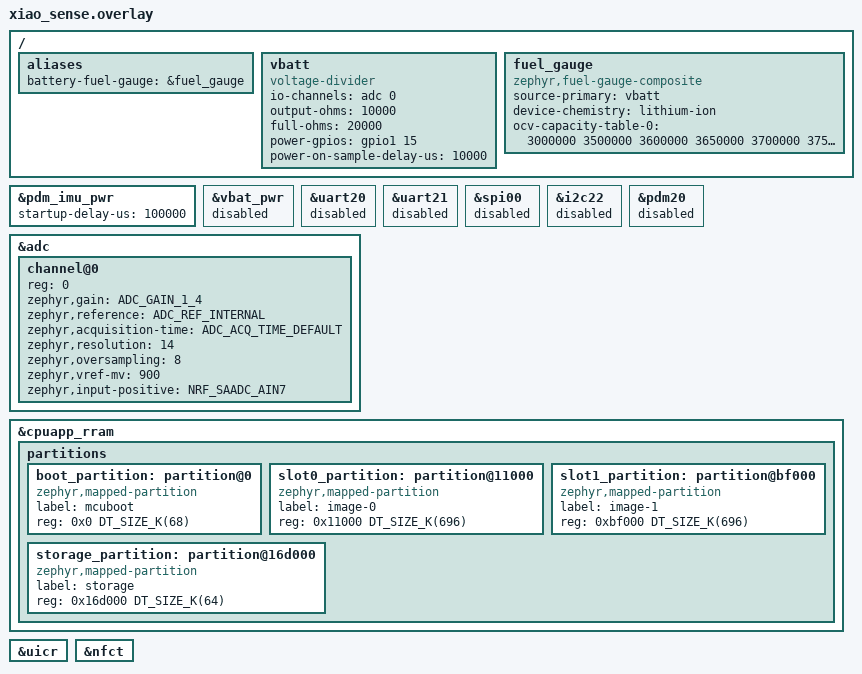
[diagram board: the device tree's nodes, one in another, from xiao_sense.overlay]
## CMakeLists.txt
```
# SPDX-License-Identifier: Apache-2.0

cmake_minimum_required(VERSION 3.20.0)

find_package(Zephyr REQUIRED HINTS $ENV{ZEPHYR_BASE})
project(putttrack_tag)

target_sources(app PRIVATE src/main.c src/pickup_shadow_v0.c)

target_sources_ifdef(CONFIG_PUTTTRACK_XIAO_SENSE app PRIVATE src/xiao_sense.c)
target_sources_ifdef(CONFIG_PUTTTRACK_NFC_READ_LED app PRIVATE src/nfc_read_led.c)
```

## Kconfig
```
# SPDX-License-Identifier: Apache-2.0

source "Kconfig.zephyr"

menu "PuttTrack Tag options"

config PUTTTRACK_XIAO_SENSE
 bool "Use the XIAO nRF54L15 Sense single-IMU backend"
 default n

config PUTTTRACK_FIRMWARE_VERSION
 string "Application version reported over BLE"
 default "0.1.21"


config PUTTTRACK_NFC_SERVICE
	bool "Enable the experimental NFC service record"
	default n
	help
	  Build the Type 4 Tag NDEF service record and one-shot bounded
	  fast-BLE discovery window used by the PCA20072 NFC feasibility experiment.
	  This option does not make NFC an authenticated transport and does not
	  replace encrypted BLE SMP or signed OTA.

config PUTTTRACK_NFC_SYSTEM_OFF_TEST
	bool "Enable explicit NFC System OFF wake experiment"
	depends on PUTTTRACK_NFC_SERVICE
	default n
	help
	  Add an encrypted BLE SMP command that enters System OFF after a short
	  delay. NFC field sensing remains armed as a wake source. This is an
	  explicit laboratory operation only; normal power policies never enter
	  System OFF automatically.

config PUTTTRACK_NFC_READ_LED
	bool "Flash board user LED on a complete NDEF read event"
	depends on PUTTTRACK_NFC_SERVICE && GPIO
	default n
	help
	  Temporary bench feedback: 150 ms pulse, at most once per second.
	  Indicates a tag-side read event, not reader CRC success or BLE identity.

endmenu
```

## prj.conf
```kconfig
# Repository-owned PuttTrack Tag firmware: BLE identity/health, raw motion and OTA.

CONFIG_BOOTLOADER_MCUBOOT=y
CONFIG_MCUBOOT_IMGTOOL_SIGN_VERSION="0.1.21+0"

# MCUboot image management over encrypted BLE SMP.
CONFIG_NET_BUF=y
CONFIG_ZCBOR=y
CONFIG_CRC=y
CONFIG_FLASH=y
CONFIG_FLASH_MAP=y
CONFIG_STREAM_FLASH=y
CONFIG_IMG_MANAGER=y
CONFIG_MCUMGR=y
CONFIG_MCUMGR_GRP_IMG=y
CONFIG_MCUMGR_GRP_OS=y
CONFIG_MCUMGR_TRANSPORT_BT=y
CONFIG_MCUMGR_TRANSPORT_BT_REASSEMBLY=y
CONFIG_MCUMGR_TRANSPORT_BT_CONN_PARAM_CONTROL=y
CONFIG_MCUMGR_TRANSPORT_BT_PERM_RW_ENCRYPT=y
CONFIG_MCUMGR_TRANSPORT_NETBUF_SIZE=8192
CONFIG_MCUMGR_TRANSPORT_WORKQUEUE_STACK_SIZE=4608

# BLE peripheral and secure connections. The lab build uses encrypted Just Works
# pairing; authenticated/MITM access needs a future physical or OOB workflow.
CONFIG_BT=y
CONFIG_BT_PERIPHERAL=y
CONFIG_BT_SMP=y
CONFIG_BT_DEVICE_NAME="PuttTrack-Tag-v0.1"
CONFIG_BT_MAX_CONN=1
CONFIG_BT_L2CAP_TX_MTU=498
CONFIG_BT_BUF_ACL_RX_SIZE=502
CONFIG_BT_BUF_ACL_TX_SIZE=502
CONFIG_BT_CTLR_DATA_LENGTH_MAX=251

# Tag sensors enabled by the upstream nrf54l15tag board definition.
CONFIG_SENSOR=y
CONFIG_I2C=y
CONFIG_SPI=y
CONFIG_ADXL367=y
CONFIG_ADXL367_TRIGGER_GLOBAL_THREAD=y
CONFIG_ADXL367_ACTIVITY_THRESHOLD=200
CONFIG_ADXL367_ACTIVITY_TIME=2
CONFIG_ADXL367_INACTIVITY_DETECTION_MODE=n
CONFIG_BMI270=y
CONFIG_BMI270_TRIGGER_NONE=y

# Allow the application to suspend the unused BMI270 SPI controller and apply
# its low-power pinctrl state while the Tag is idle.
CONFIG_PM_DEVICE=y

# The official nRF54L15 Tag fuel-gauge setup samples VDD with SAADC and maps
# the CR2032 open-circuit voltage to an explicitly approximate percentage.
CONFIG_ADC=y
CONFIG_FUEL_GAUGE=y
CONFIG_FUEL_GAUGE_COMPOSITE=y

# Stable hardware identity, boot identity and reset diagnostics.
CONFIG_HWINFO=y
CONFIG_ENTROPY_GENERATOR=y
CONFIG_REBOOT=y

# The Tag has no selected debug UART. Runtime diagnostics are part of the BLE
# status record rather than an inaccessible console.
CONFIG_CONSOLE=n
CONFIG_UART_CONSOLE=n
CONFIG_SERIAL=n
CONFIG_UART_MCUMGR=n
CONFIG_MCUMGR_TRANSPORT_UART=n
CONFIG_SHELL=n
CONFIG_LOG=n

CONFIG_MAIN_STACK_SIZE=4096
CONFIG_SYSTEM_WORKQUEUE_STACK_SIZE=4096

# Keep the commissioned BLE identity and bonds across System OFF and reset.
CONFIG_SETTINGS=y
CONFIG_BT_SETTINGS=y
CONFIG_NVS=y
CONFIG_SETTINGS_NVS=y
CONFIG_BT_DEVICE_NAME_DYNAMIC=y
```

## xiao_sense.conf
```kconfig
# Repository-owned PuttTrack Tag firmware: BLE identity/health, raw motion and OTA.

CONFIG_BOOTLOADER_MCUBOOT=y
CONFIG_MCUBOOT_IMGTOOL_SIGN_VERSION="0.2.7+0"

# MCUboot image management over encrypted BLE SMP.
CONFIG_NET_BUF=y
CONFIG_ZCBOR=y
CONFIG_CRC=y
CONFIG_FLASH=y
CONFIG_FLASH_MAP=y
CONFIG_STREAM_FLASH=y
CONFIG_IMG_MANAGER=y
CONFIG_MCUMGR=y
CONFIG_MCUMGR_GRP_IMG=y
CONFIG_MCUMGR_GRP_OS=y
CONFIG_MCUMGR_TRANSPORT_BT=y
CONFIG_MCUMGR_TRANSPORT_BT_REASSEMBLY=y
CONFIG_MCUMGR_TRANSPORT_BT_CONN_PARAM_CONTROL=y
CONFIG_MCUMGR_TRANSPORT_BT_PERM_RW_ENCRYPT=y
CONFIG_MCUMGR_TRANSPORT_NETBUF_SIZE=8192
CONFIG_MCUMGR_TRANSPORT_WORKQUEUE_STACK_SIZE=4608

# BLE peripheral and secure connections. The lab build uses encrypted Just Works
# pairing; authenticated/MITM access needs a future physical or OOB workflow.
CONFIG_BT=y
CONFIG_BT_PERIPHERAL=y
CONFIG_BT_SMP=y
CONFIG_BT_MAX_PAIRED=2
CONFIG_BT_DEVICE_NAME="PuttTrack-Tag-v0.1"
CONFIG_BT_MAX_CONN=1
CONFIG_BT_L2CAP_TX_MTU=498
CONFIG_BT_BUF_ACL_RX_SIZE=502
CONFIG_BT_BUF_ACL_TX_SIZE=502
CONFIG_BT_CTLR_DATA_LENGTH_MAX=251

# XIAO owns one LSM6DS3TR-C via the serialized register backend.
CONFIG_PUTTTRACK_XIAO_SENSE=y
CONFIG_PUTTTRACK_FIRMWARE_VERSION="0.2.7"
CONFIG_SENSOR=y
CONFIG_I2C=y
CONFIG_GPIO=y
CONFIG_REGULATOR=y
CONFIG_REGULATOR_FIXED=y
CONFIG_LSM6DSL=n
CONFIG_PM_DEVICE=y
CONFIG_ADC=y
CONFIG_FUEL_GAUGE=y
CONFIG_FUEL_GAUGE_COMPOSITE=y

# Stable hardware identity, boot identity and reset diagnostics.
CONFIG_HWINFO=y
CONFIG_ENTROPY_GENERATOR=y
CONFIG_REBOOT=y

# The Tag has no selected debug UART. Runtime diagnostics are part of the BLE
# status record rather than an inaccessible console.
CONFIG_CONSOLE=n
CONFIG_UART_CONSOLE=n
CONFIG_SERIAL=n
CONFIG_UART_MCUMGR=n
CONFIG_MCUMGR_TRANSPORT_UART=n
CONFIG_SHELL=n
CONFIG_LOG=n

CONFIG_MAIN_STACK_SIZE=4096
CONFIG_SYSTEM_WORKQUEUE_STACK_SIZE=4096

# NFC Type 4 read/write service and an explicit, recoverable System OFF experiment.
CONFIG_PUTTTRACK_NFC_SERVICE=y
CONFIG_NFC_T4T_NRFXLIB=y
CONFIG_NFC_NDEF=y
CONFIG_NFC_NDEF_MSG=y
CONFIG_NFC_NDEF_RECORD=y
CONFIG_NFC_NDEF_URI_REC=y
CONFIG_NFC_NDEF_URI_MSG=y
CONFIG_PUTTTRACK_NFC_SYSTEM_OFF_TEST=y
CONFIG_POWEROFF=y

# Preserve BLE identity and pairing keys across MCUboot trial/rollback/reset.
CONFIG_SETTINGS=y
CONFIG_BT_SETTINGS=y
CONFIG_NVS=y
CONFIG_SETTINGS_NVS=y

CONFIG_BT_DEVICE_NAME_DYNAMIC=y
CONFIG_PUTTTRACK_NFC_READ_LED=y
```

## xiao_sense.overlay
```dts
/* Seeed XIAO Sense: own the IMU supply sequencing; keep OTA slot layout. */
/delete-node/ &imu_power_default_on;
&pdm_imu_pwr {
 /delete-property/ regulator-boot-on;
 startup-delay-us = <100000>;
};
/* The divider driver owns VBAT_EN and only powers it during measurement. */
&vbat_pwr { status = "disabled"; };
&uart20 { status = "disabled"; };
&uart21 { status = "disabled"; };
&spi00 { status = "disabled"; };
&i2c22 { status = "disabled"; };
&pdm20 { status = "disabled"; };
/ {
 aliases { battery-fuel-gauge = &fuel_gauge; };
 vbatt: vbatt {
  compatible = "voltage-divider";
  io-channels = <&adc 0>;
  output-ohms = <10000>;
  full-ohms = <20000>;
  power-gpios = <&gpio1 15 GPIO_ACTIVE_HIGH>;
  power-on-sample-delay-us = <10000>;
 };
 fuel_gauge: fuel_gauge {
  compatible = "zephyr,fuel-gauge-composite";
  source-primary = <&vbatt>;
  device-chemistry = "lithium-ion";
  /* Generic Li-ion OCV estimate, NOT a calibrated battery or presence detector. */
  ocv-capacity-table-0 = <3000000 3500000 3600000 3650000 3700000
                        3750000 3800000 3900000 4000000 4100000 4200000>;

 };
};
&adc {
 #address-cells = <1>;
 #size-cells = <0>;
 channel@0 {
  reg = <0>;
  zephyr,gain = "ADC_GAIN_1_4";
  zephyr,reference = "ADC_REF_INTERNAL";
  zephyr,acquisition-time = <ADC_ACQ_TIME_DEFAULT>;
  zephyr,resolution = <14>;
  zephyr,oversampling = <8>;
  zephyr,vref-mv = <900>;
  zephyr,input-positive = <NRF_SAADC_AIN7>;
 };
};
/delete-node/ &boot_partition;
/delete-node/ &slot0_partition;
/delete-node/ &slot1_partition;
/delete-node/ &storage_partition;

&cpuapp_rram {
	partitions {
		boot_partition: partition@0 {
			compatible = "zephyr,mapped-partition";
			label = "mcuboot";
			reg = <0x0 DT_SIZE_K(68)>;
		};

		slot0_partition: partition@11000 {
			compatible = "zephyr,mapped-partition";
			label = "image-0";
			reg = <0x11000 DT_SIZE_K(696)>;
		};

		slot1_partition: partition@bf000 {
			compatible = "zephyr,mapped-partition";
			label = "image-1";
			reg = <0xbf000 DT_SIZE_K(696)>;
		};

		storage_partition: partition@16d000 {
			compatible = "zephyr,mapped-partition";
			label = "storage";
			reg = <0x16d000 DT_SIZE_K(64)>;
		};
	};
};

&uicr { /delete-property/ nfct-pins-as-gpios; };
&nfct { status = "okay"; };
```

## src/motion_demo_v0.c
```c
#include "motion_demo_v0.h"

#include <string.h>

#define MICRO_F 1000000.0f
#define BASELINE_WINDOW_US 1000000ULL
#define IMPULSE_WINDOW_BEFORE_US 100000ULL
#define IMPULSE_WINDOW_AFTER_US 500000ULL
#define GYRO_WINDOW_US 1000000ULL
#define TRACKING_WINDOW_US 500000ULL
#define MIN_BASELINE_DURATION_US 900000ULL
#define MIN_TRACKING_SAMPLES 20U

_Static_assert(sizeof(struct motion_demo_v0) <=
                   MOTION_DEMO_V0_CONTEXT_RAM_BUDGET_BYTES,
               "motion demo context exceeds the research RAM budget");

struct motion_demo_window_stats {
    uint16_t count;
    uint64_t first_us;
    uint64_t last_us;
    float accel_norm_mean;
    float accel_norm_m2;
    float gyro_norm_sum;
    float gyro_norm_sq_sum;
    float gyro_vector_sum[3];
    bool invalid;
    bool gyro_clipped;
};

static float demo_absf(float value)
{
    return value < 0.0f ? -value : value;
}

static float demo_sqrtf(float value)
{
    if (value <= 0.0f) {
        return 0.0f;
    }
    float estimate = value > 1.0f ? value : 1.0f;
    for (size_t iteration = 0; iteration < 16U; iteration++) {
        estimate = 0.5f * (estimate + value / estimate);
    }
    return estimate;
}

static float vector_norm_micro(const int32_t vector[3])
{
    float squared = 0.0f;
    for (size_t axis = 0; axis < 3U; axis++) {
        float value = (float)vector[axis] / MICRO_F;
        squared += value * value;
    }
    return demo_sqrtf(squared);
}

static bool sample_is_valid(const struct motion_demo_v0_sample *sample)
{
    return sample->bmi270_valid && sample->sensor_error_bits == 0U;
}

static bool sample_gyro_clipped(const struct motion_demo_v0_sample *sample)
{
    for (size_t axis = 0; axis < 3U; axis++) {
        int64_t value = sample->gyro_micro_rads[axis];
        if (value < 0) {
            value = -value;
        }
        if (value >= MOTION_DEMO_V0_GYRO_CLIP_MICRO_RADS) {
            return true;
        }
    }
    return false;
}

static bool sample_is_active(const struct motion_demo_v0_sample *sample)
{
    float accel_norm = vector_norm_micro(sample->accel_micro_ms2);
    float gyro_norm = vector_norm_micro(sample->gyro_micro_rads);
    return demo_absf(accel_norm - MOTION_DEMO_V0_GRAVITY_MPS2) >=
               MOTION_DEMO_V0_ONSET_ACCEL_DEVIATION_MPS2 ||
           gyro_norm >= MOTION_DEMO_V0_ONSET_GYRO_RADS;
}

static uint16_t oldest_index(const struct motion_demo_v0 *context)
{
    return (uint16_t)((context->write_index + MOTION_DEMO_V0_BUFFER_SAMPLES -
                       context->count) %
                      MOTION_DEMO_V0_BUFFER_SAMPLES);
}

static const struct motion_demo_v0_sample *sample_at(
    const struct motion_demo_v0 *context, uint16_t logical_index)
{
    uint16_t index = (uint16_t)((oldest_index(context) + logical_index) %
                                MOTION_DEMO_V0_BUFFER_SAMPLES);
    return &context->samples[index];
}

static void store_sample(struct motion_demo_v0 *context,
                         const struct motion_demo_v0_sample *sample)
{
    context->samples[context->write_index] = *sample;
    context->write_index = (uint16_t)((context->write_index + 1U) %
                                      MOTION_DEMO_V0_BUFFER_SAMPLES);
    if (context->count < MOTION_DEMO_V0_BUFFER_SAMPLES) {
        context->count++;
    }
}

static bool set_state(struct motion_demo_v0 *context,
                      enum motion_demo_v0_state state,
                      uint64_t transition_us)
{
    if (context->state == state) {
        return false;
    }
    context->state = state;
    context->last_transition_us = transition_us;
    context->state_transition_count++;
    return true;
}

static void reset_candidate_features(struct motion_demo_v0 *context)
{
    context->baseline_stationary = false;
    context->pickup_rule_passed = false;
    context->rolling_rule_passed = false;
    context->vertical_impulse_milli_mps = 0;
    context->gyro_mean_milli_rads = 0;
    context->axis_consistency_milli = 0;
    context->onset_sequence = 0U;
    context->onset_us = 0U;
}

static void reset_history_after_fault(struct motion_demo_v0 *context)
{
    context->write_index = 0U;
    context->count = 0U;
    reset_candidate_features(context);
}

static void window_stats_add(struct motion_demo_window_stats *stats,
                             const struct motion_demo_v0_sample *sample)
{
    float accel_norm = vector_norm_micro(sample->accel_micro_ms2);
    float gyro_norm = vector_norm_micro(sample->gyro_micro_rads);
    stats->count++;
    if (stats->count == 1U) {
        stats->first_us = sample->source_monotonic_us;
        stats->accel_norm_mean = accel_norm;
    } else {
        float delta = accel_norm - stats->accel_norm_mean;
        stats->accel_norm_mean += delta / (float)stats->count;
        stats->accel_norm_m2 += delta *
                               (accel_norm - stats->accel_norm_mean);
    }
    stats->last_us = sample->source_monotonic_us;
    stats->gyro_norm_sum += gyro_norm;
    stats->gyro_norm_sq_sum += gyro_norm * gyro_norm;
    for (size_t axis = 0; axis < 3U; axis++) {
        stats->gyro_vector_sum[axis] +=
            (float)sample->gyro_micro_rads[axis] / MICRO_F;
    }
    stats->invalid |= !sample_is_valid(sample);
    stats->gyro_clipped |= sample_gyro_clipped(sample);
}

static struct motion_demo_window_stats window_stats(
    const struct motion_demo_v0 *context, uint64_t start_us, uint64_t end_us)
{
    struct motion_demo_window_stats stats = {0};
    for (uint16_t index = 0U; index < context->count; index++) {
        const struct motion_demo_v0_sample *sample = sample_at(context, index);
        if (sample->source_monotonic_us >= start_us &&
            sample->source_monotonic_us < end_us) {
            window_stats_add(&stats, sample);
        }
    }
    return stats;
}

static float window_accel_std(const struct motion_demo_window_stats *stats)
{
    if (stats->count < 2U) {
        return 0.0f;
    }
    return demo_sqrtf(stats->accel_norm_m2 / (float)stats->count);
}

static float window_gyro_rms(const struct motion_demo_window_stats *stats)
{
    if (stats->count == 0U) {
        return 0.0f;
    }
    return demo_sqrtf(stats->gyro_norm_sq_sum / (float)stats->count);
}

static float window_gyro_mean(const struct motion_demo_window_stats *stats)
{
    return stats->count == 0U ? 0.0f :
           stats->gyro_norm_sum / (float)stats->count;
}

static float window_axis_consistency(
    const struct motion_demo_window_stats *stats)
{
    float mean_norm = window_gyro_mean(stats);
    if (stats->count == 0U || mean_norm <= 0.000001f) {
        return 0.0f;
    }
    float squared = 0.0f;
    for (size_t axis = 0; axis < 3U; axis++) {
        float mean = stats->gyro_vector_sum[axis] / (float)stats->count;
        squared += mean * mean;
    }
    return demo_sqrtf(squared) / mean_norm;
}

static bool stationary_window(const struct motion_demo_v0 *context,
                              uint64_t end_us)
{
    uint64_t start_us = end_us > BASELINE_WINDOW_US ?
                        end_us - BASELINE_WINDOW_US : 0U;
    struct motion_demo_window_stats stats =
        window_stats(context, start_us, end_us + 1U);
    if (stats.count < MOTION_DEMO_V0_REQUIRED_BASELINE_SAMPLES ||
        stats.invalid || stats.last_us <= stats.first_us ||
        stats.last_us - stats.first_us < MIN_BASELINE_DURATION_US) {
        return false;
    }
    return window_accel_std(&stats) <=
               MOTION_DEMO_V0_STATIONARY_ACCEL_STD_MAX_MPS2 &&
           window_gyro_rms(&stats) <=
               MOTION_DEMO_V0_STATIONARY_GYRO_RMS_MAX_RADS;
}

static bool onset_block_ready(const struct motion_demo_v0 *context,
                              uint16_t *onset_logical_index)
{
    if (context->count < MOTION_DEMO_V0_ONSET_WINDOW_SAMPLES) {
        return false;
    }
    uint16_t start = (uint16_t)(context->count -
                                MOTION_DEMO_V0_ONSET_WINDOW_SAMPLES);
    uint16_t active = 0U;
    for (uint16_t offset = 0U;
         offset < MOTION_DEMO_V0_ONSET_WINDOW_SAMPLES; offset++) {
        const struct motion_demo_v0_sample *sample =
            sample_at(context, (uint16_t)(start + offset));
        active += sample_is_active(sample) ? 1U : 0U;
    }
    if (active < MOTION_DEMO_V0_ONSET_ACTIVE_SAMPLES) {
        return false;
    }
    *onset_logical_index = start;
    return true;
}

static bool baseline_before_onset(const struct motion_demo_v0 *context,
                                  uint64_t onset_us,
                                  float mean_accel[3])
{
    uint64_t start_us = onset_us > BASELINE_WINDOW_US ?
                        onset_us - BASELINE_WINDOW_US : 0U;
    struct motion_demo_window_stats stats =
        window_stats(context, start_us, onset_us);
    if (stats.count < MOTION_DEMO_V0_REQUIRED_BASELINE_SAMPLES ||
        stats.invalid || stats.last_us <= stats.first_us ||
        stats.last_us - stats.first_us < MIN_BASELINE_DURATION_US ||
        window_accel_std(&stats) >
            MOTION_DEMO_V0_STATIONARY_ACCEL_STD_MAX_MPS2 ||
        window_gyro_rms(&stats) >
            MOTION_DEMO_V0_STATIONARY_GYRO_RMS_MAX_RADS) {
        return false;
    }

    uint16_t count = 0U;
    for (uint16_t index = 0U; index < context->count; index++) {
        const struct motion_demo_v0_sample *sample = sample_at(context, index);
        if (sample->source_monotonic_us < start_us ||
            sample->source_monotonic_us >= onset_us) {
            continue;
        }
        for (size_t axis = 0U; axis < 3U; axis++) {
            mean_accel[axis] +=
                (float)sample->accel_micro_ms2[axis] / MICRO_F;
        }
        count++;
    }
    if (count == 0U) {
        return false;
    }
    for (size_t axis = 0U; axis < 3U; axis++) {
        mean_accel[axis] /= (float)count;
    }
    return true;
}

static bool normalize3(float vector[3])
{
    float squared = vector[0] * vector[0] + vector[1] * vector[1] +
                    vector[2] * vector[2];
    float magnitude = demo_sqrtf(squared);
    if (magnitude <= 0.000001f) {
        return false;
    }
    for (size_t axis = 0U; axis < 3U; axis++) {
        vector[axis] /= magnitude;
    }
    return true;
}

static void propagate_up(float up[3], const int32_t gyro_micro[3], float dt)
{
    float gyro[3];
    for (size_t axis = 0U; axis < 3U; axis++) {
        gyro[axis] = (float)gyro_micro[axis] / MICRO_F;
    }
    float cross[3] = {
        gyro[1] * up[2] - gyro[2] * up[1],
        gyro[2] * up[0] - gyro[0] * up[2],
        gyro[0] * up[1] - gyro[1] * up[0],
    };
    for (size_t axis = 0U; axis < 3U; axis++) {
        up[axis] -= cross[axis] * dt;
    }
    (void)normalize3(up);
}

static float dot_accel_up(const int32_t accel_micro[3], const float up[3])
{
    float value = 0.0f;
    for (size_t axis = 0U; axis < 3U; axis++) {
        value += ((float)accel_micro[axis] / MICRO_F) * up[axis];
    }
    return value;
}

static int32_t to_milli(float value)
{
    float scaled = value * 1000.0f;
    return (int32_t)(scaled >= 0.0f ? scaled + 0.5f : scaled - 0.5f);
}

static bool evaluate_pending_candidate(struct motion_demo_v0 *context,
                                       uint64_t now_us)
{
    float up[3] = {0.0f, 0.0f, 0.0f};
    if (!baseline_before_onset(context, context->onset_us, up) ||
        !normalize3(up)) {
        context->quality_flags =
            MOTION_DEMO_V0_QUALITY_BASELINE_NOT_STATIONARY;
        context->baseline_stationary = false;
        return set_state(context, MOTION_DEMO_V0_UNKNOWN_QUALITY, now_us);
    }
    context->baseline_stationary = true;

    uint64_t propagation_start = context->onset_us - BASELINE_WINDOW_US;
    uint64_t impulse_start = context->onset_us - IMPULSE_WINDOW_BEFORE_US;
    uint64_t impulse_end = context->onset_us + IMPULSE_WINDOW_AFTER_US;
    uint64_t gyro_end = context->onset_us + GYRO_WINDOW_US;
    float impulse = 0.0f;
    float gyro_norm_sum = 0.0f;
    float gyro_vector_sum[3] = {0.0f, 0.0f, 0.0f};
    uint16_t impulse_count = 0U;
    uint16_t gyro_count = 0U;
    bool clipped = false;
    const struct motion_demo_v0_sample *previous = NULL;
    const struct motion_demo_v0_sample *previous_impulse = NULL;

    for (uint16_t index = 0U; index < context->count; index++) {
        const struct motion_demo_v0_sample *sample = sample_at(context, index);
        if (sample->source_monotonic_us < propagation_start ||
            sample->source_monotonic_us >= gyro_end) {
            continue;
        }
        if (!sample_is_valid(sample)) {
            context->quality_flags =
                MOTION_DEMO_V0_QUALITY_SENSOR_INVALID;
            return set_state(context, MOTION_DEMO_V0_UNKNOWN_QUALITY, now_us);
        }
        if (previous != NULL) {
            float dt = (float)(sample->source_monotonic_us -
                               previous->source_monotonic_us) / MICRO_F;
            propagate_up(up, previous->gyro_micro_rads, dt);
        }

        if (sample->source_monotonic_us >= impulse_start &&
            sample->source_monotonic_us < impulse_end) {
            impulse_count++;
            if (previous_impulse != NULL) {
                float dt = (float)(sample->source_monotonic_us -
                                   previous_impulse->source_monotonic_us) /
                           MICRO_F;
                float dynamic = dot_accel_up(sample->accel_micro_ms2, up) -
                                MOTION_DEMO_V0_GRAVITY_MPS2;
                if (dynamic > 0.0f) {
                    impulse += dynamic * dt;
                }
            }
            previous_impulse = sample;
        }

        if (sample->source_monotonic_us >= context->onset_us) {
            float gyro_norm = vector_norm_micro(sample->gyro_micro_rads);
            gyro_norm_sum += gyro_norm;
            for (size_t axis = 0U; axis < 3U; axis++) {
                gyro_vector_sum[axis] +=
                    (float)sample->gyro_micro_rads[axis] / MICRO_F;
            }
            gyro_count++;
            clipped |= sample_gyro_clipped(sample);
        }
        previous = sample;
    }

    if (impulse_count < MOTION_DEMO_V0_REQUIRED_IMPULSE_SAMPLES ||
        gyro_count < MOTION_DEMO_V0_REQUIRED_GYRO_SAMPLES) {
        context->quality_flags =
            MOTION_DEMO_V0_QUALITY_INSUFFICIENT_WINDOW;
        return set_state(context, MOTION_DEMO_V0_UNKNOWN_QUALITY, now_us);
    }

    float gyro_mean = gyro_norm_sum / (float)gyro_count;
    float mean_vector_sq = 0.0f;
    for (size_t axis = 0U; axis < 3U; axis++) {
        float mean = gyro_vector_sum[axis] / (float)gyro_count;
        mean_vector_sq += mean * mean;
    }
    float axis_consistency = gyro_mean > 0.000001f ?
                             demo_sqrtf(mean_vector_sq) / gyro_mean : 0.0f;

    context->vertical_impulse_milli_mps = to_milli(impulse);
    context->gyro_mean_milli_rads = to_milli(gyro_mean);
    context->axis_consistency_milli = to_milli(axis_consistency);
    context->pickup_rule_passed =
        !clipped && impulse > MOTION_DEMO_V0_PICKUP_IMPULSE_MIN_MPS &&
        gyro_mean < MOTION_DEMO_V0_PICKUP_GYRO_MEAN_MAX_RADS &&
        axis_consistency < MOTION_DEMO_V0_PICKUP_AXIS_MAX;
    context->rolling_rule_passed =
        gyro_mean >= MOTION_DEMO_V0_ROLLING_GYRO_MEAN_MIN_RADS &&
        axis_consistency >= MOTION_DEMO_V0_ROLLING_AXIS_MIN;
    context->quality_flags = clipped ?
        MOTION_DEMO_V0_QUALITY_GYRO_CLIPPED : 0U;

    if (context->pickup_rule_passed) {
        context->last_event = MOTION_DEMO_V0_EVENT_PICKUP_FROM_REST;
        context->last_event_us = now_us;
        context->event_count++;
        return set_state(context, MOTION_DEMO_V0_CARRIED_CANDIDATE, now_us);
    }
    if (context->rolling_rule_passed) {
        return set_state(context, MOTION_DEMO_V0_ROLLING_CANDIDATE, now_us);
    }
    if (clipped) {
        return set_state(context, MOTION_DEMO_V0_UNKNOWN_QUALITY, now_us);
    }
    return set_state(context, MOTION_DEMO_V0_ACTIVE_UNKNOWN, now_us);
}

static bool recent_window_is_rolling(const struct motion_demo_v0 *context,
                                     uint64_t now_us)
{
    uint64_t start_us = now_us > TRACKING_WINDOW_US ?
                        now_us - TRACKING_WINDOW_US : 0U;
    struct motion_demo_window_stats stats =
        window_stats(context, start_us, now_us + 1U);
    if (stats.count < MIN_TRACKING_SAMPLES || stats.invalid) {
        return false;
    }
    return window_gyro_mean(&stats) >=
               MOTION_DEMO_V0_TRACKING_GYRO_MEAN_MIN_RADS &&
           window_axis_consistency(&stats) >=
               MOTION_DEMO_V0_TRACKING_AXIS_MIN;
}

void motion_demo_v0_init(struct motion_demo_v0 *context)
{
    memset(context, 0, sizeof(*context));
    context->state = MOTION_DEMO_V0_BOOTSTRAP;
    context->last_event = MOTION_DEMO_V0_EVENT_NONE;
}

bool motion_demo_v0_push(struct motion_demo_v0 *context,
                         const struct motion_demo_v0_sample *sample)
{
    bool changed = false;
    uint32_t fault_flags = 0U;

    if (context->have_previous) {
        if (sample->sequence != context->previous_sequence + 1U) {
            fault_flags |= MOTION_DEMO_V0_QUALITY_SEQUENCE_GAP;
        }
        if (sample->source_monotonic_us <= context->previous_time_us) {
            fault_flags |= MOTION_DEMO_V0_QUALITY_TIME_REGRESSION;
        }
    }
    if (!sample_is_valid(sample)) {
        fault_flags |= MOTION_DEMO_V0_QUALITY_SENSOR_INVALID;
    }

    if (fault_flags != 0U) {
        reset_history_after_fault(context);
        context->quality_flags = fault_flags;
        changed |= set_state(context, MOTION_DEMO_V0_UNKNOWN_QUALITY,
                             sample->source_monotonic_us);
    }

    store_sample(context, sample);
    context->previous_sequence = sample->sequence;
    context->previous_time_us = sample->source_monotonic_us;
    context->have_previous = true;

    if (fault_flags != 0U) {
        return changed;
    }

    bool stationary = stationary_window(context, sample->source_monotonic_us);
    if (context->state == MOTION_DEMO_V0_BOOTSTRAP ||
        context->state == MOTION_DEMO_V0_UNKNOWN_QUALITY) {
        if (stationary) {
            context->quality_flags = 0U;
            reset_candidate_features(context);
            changed |= set_state(context, MOTION_DEMO_V0_STATIONARY,
                                 sample->source_monotonic_us);
        }
        return changed;
    }

    if (context->state == MOTION_DEMO_V0_STATIONARY) {
        uint16_t onset_index;
        if (onset_block_ready(context, &onset_index)) {
            const struct motion_demo_v0_sample *onset =
                sample_at(context, onset_index);
            context->onset_sequence = onset->sequence;
            context->onset_us = onset->source_monotonic_us;
            context->baseline_stationary = true;
            context->pickup_rule_passed = false;
            context->rolling_rule_passed = false;
            context->quality_flags = 0U;
            changed |= set_state(context, MOTION_DEMO_V0_ACTIVE_PENDING,
                                 sample->source_monotonic_us);
        }
        return changed;
    }

    if (context->state == MOTION_DEMO_V0_ACTIVE_PENDING) {
        if (sample->source_monotonic_us >=
            context->onset_us + GYRO_WINDOW_US) {
            changed |= evaluate_pending_candidate(context,
                                                  sample->source_monotonic_us);
        }
        return changed;
    }

    if (stationary &&
        (context->state != MOTION_DEMO_V0_CARRIED_CANDIDATE ||
         sample->source_monotonic_us - context->last_event_us >= 1500000ULL)) {
        context->quality_flags = 0U;
        context->rolling_rule_passed = false;
        changed |= set_state(context, MOTION_DEMO_V0_STATIONARY,
                             sample->source_monotonic_us);
        return changed;
    }

    bool rolling = recent_window_is_rolling(context,
                                             sample->source_monotonic_us);
    if (context->state == MOTION_DEMO_V0_ROLLING_CANDIDATE && !rolling) {
        context->rolling_rule_passed = false;
        changed |= set_state(context, MOTION_DEMO_V0_ACTIVE_UNKNOWN,
                             sample->source_monotonic_us);
    }

    return changed;
}

void motion_demo_v0_get_snapshot(const struct motion_demo_v0 *context,
                                 struct motion_demo_v0_snapshot *snapshot)
{
    snapshot->state = context->state;
    snapshot->last_event = context->last_event;
    snapshot->quality_flags = context->quality_flags;
    snapshot->state_transition_count = context->state_transition_count;
    snapshot->event_count = context->event_count;
    snapshot->onset_sequence = context->onset_sequence;
    snapshot->last_transition_us = context->last_transition_us;
    snapshot->last_event_us = context->last_event_us;
    snapshot->vertical_impulse_milli_mps =
        context->vertical_impulse_milli_mps;
    snapshot->gyro_mean_milli_rads = context->gyro_mean_milli_rads;
    snapshot->axis_consistency_milli = context->axis_consistency_milli;
    snapshot->buffered_samples = context->count;
    snapshot->baseline_stationary = context->baseline_stationary;
    snapshot->pickup_rule_passed = context->pickup_rule_passed;
    snapshot->rolling_rule_passed = context->rolling_rule_passed;
}

const char *motion_demo_v0_state_name(enum motion_demo_v0_state state)
{
    switch (state) {
    case MOTION_DEMO_V0_STATIONARY:
        return "STATIONARY";
    case MOTION_DEMO_V0_ACTIVE_PENDING:
        return "ACTIVE_PENDING";
    case MOTION_DEMO_V0_ROLLING_CANDIDATE:
        return "ROLLING_CANDIDATE";
    case MOTION_DEMO_V0_CARRIED_CANDIDATE:
        return "CARRIED_CANDIDATE";
    case MOTION_DEMO_V0_ACTIVE_UNKNOWN:
        return "ACTIVE_UNKNOWN";
    case MOTION_DEMO_V0_UNKNOWN_QUALITY:
        return "UNKNOWN_QUALITY";
    case MOTION_DEMO_V0_BOOTSTRAP:
    default:
        return "BOOTSTRAP";
    }
}

const char *motion_demo_v0_event_name(enum motion_demo_v0_event event)
{
    return event == MOTION_DEMO_V0_EVENT_PICKUP_FROM_REST ?
           "PICKUP_FROM_REST" : "NONE";
}
```

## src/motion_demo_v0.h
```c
#ifndef PUTTTRACK_MOTION_DEMO_V0_H_
#define PUTTTRACK_MOTION_DEMO_V0_H_

#include <stdbool.h>
#include <stddef.h>
#include <stdint.h>

#ifdef __cplusplus
extern "C" {
#endif

#define MOTION_DEMO_V0_BUFFER_SAMPLES 128U
#define MOTION_DEMO_V0_CONTEXT_RAM_BUDGET_BYTES 8192U
#define MOTION_DEMO_V0_DETECTOR_ID "mcu_motion_demo_v0"
#define MOTION_DEMO_V0_PICKUP_CONFIG_SHA256 \
    "62c82c1a313f70912a5bb6c2f53c635fe179c537cdb3738dbc5d2a347050c8ad"

/* Frozen stationary-start pickup V0 values, in SI units. */
#define MOTION_DEMO_V0_GRAVITY_MPS2 9.80665f
#define MOTION_DEMO_V0_STATIONARY_ACCEL_STD_MAX_MPS2 0.15f
#define MOTION_DEMO_V0_STATIONARY_GYRO_RMS_MAX_RADS 0.08f
#define MOTION_DEMO_V0_ONSET_ACCEL_DEVIATION_MPS2 0.5f
#define MOTION_DEMO_V0_ONSET_GYRO_RADS 0.25f
#define MOTION_DEMO_V0_ONSET_WINDOW_SAMPLES 10U
#define MOTION_DEMO_V0_ONSET_ACTIVE_SAMPLES 6U
#define MOTION_DEMO_V0_PICKUP_IMPULSE_MIN_MPS 0.5f
#define MOTION_DEMO_V0_PICKUP_GYRO_MEAN_MAX_RADS 10.0f
#define MOTION_DEMO_V0_PICKUP_AXIS_MAX 0.75f

/* Post-hoc rolling display gate. It is a demo candidate, not product truth. */
#define MOTION_DEMO_V0_ROLLING_GYRO_MEAN_MIN_RADS 8.0f
#define MOTION_DEMO_V0_ROLLING_AXIS_MIN 0.90f
#define MOTION_DEMO_V0_TRACKING_GYRO_MEAN_MIN_RADS 2.0f
#define MOTION_DEMO_V0_TRACKING_AXIS_MIN 0.85f

#define MOTION_DEMO_V0_GYRO_CLIP_MICRO_RADS 34208453
#define MOTION_DEMO_V0_REQUIRED_BASELINE_SAMPLES 40U
#define MOTION_DEMO_V0_REQUIRED_IMPULSE_SAMPLES 24U
#define MOTION_DEMO_V0_REQUIRED_GYRO_SAMPLES 40U
#define MOTION_DEMO_V0_PICKUP_EVENT_LATCH_US 5000000ULL

#define MOTION_DEMO_V0_QUALITY_SENSOR_INVALID (1U << 0)
#define MOTION_DEMO_V0_QUALITY_SEQUENCE_GAP (1U << 1)
#define MOTION_DEMO_V0_QUALITY_TIME_REGRESSION (1U << 2)
#define MOTION_DEMO_V0_QUALITY_BASELINE_NOT_STATIONARY (1U << 3)
#define MOTION_DEMO_V0_QUALITY_INSUFFICIENT_WINDOW (1U << 4)
#define MOTION_DEMO_V0_QUALITY_GYRO_CLIPPED (1U << 5)

struct motion_demo_v0_sample {
    uint32_t sequence;
    uint64_t source_monotonic_us;
    int32_t accel_micro_ms2[3];
    int32_t gyro_micro_rads[3];
    bool bmi270_valid;
    uint32_t sensor_error_bits;
};

enum motion_demo_v0_state {
    MOTION_DEMO_V0_BOOTSTRAP = 0,
    MOTION_DEMO_V0_STATIONARY = 1,
    MOTION_DEMO_V0_ACTIVE_PENDING = 2,
    MOTION_DEMO_V0_ROLLING_CANDIDATE = 3,
    MOTION_DEMO_V0_CARRIED_CANDIDATE = 4,
    MOTION_DEMO_V0_ACTIVE_UNKNOWN = 5,
    MOTION_DEMO_V0_UNKNOWN_QUALITY = 6,
};

enum motion_demo_v0_event {
    MOTION_DEMO_V0_EVENT_NONE = 0,
    MOTION_DEMO_V0_EVENT_PICKUP_FROM_REST = 1,
};

struct motion_demo_v0_snapshot {
    enum motion_demo_v0_state state;
    enum motion_demo_v0_event last_event;
    uint32_t quality_flags;
    uint32_t state_transition_count;
    uint32_t event_count;
    uint32_t onset_sequence;
    uint64_t last_transition_us;
    uint64_t last_event_us;
    int32_t vertical_impulse_milli_mps;
    int32_t gyro_mean_milli_rads;
    int32_t axis_consistency_milli;
    uint16_t buffered_samples;
    bool baseline_stationary;
    bool pickup_rule_passed;
    bool rolling_rule_passed;
};

struct motion_demo_v0 {
    struct motion_demo_v0_sample samples[MOTION_DEMO_V0_BUFFER_SAMPLES];
    uint16_t write_index;
    uint16_t count;
    enum motion_demo_v0_state state;
    enum motion_demo_v0_event last_event;
    uint32_t quality_flags;
    uint32_t state_transition_count;
    uint32_t event_count;
    uint32_t onset_sequence;
    uint64_t onset_us;
    uint64_t last_transition_us;
    uint64_t last_event_us;
    uint32_t previous_sequence;
    uint64_t previous_time_us;
    bool have_previous;
    bool baseline_stationary;
    bool pickup_rule_passed;
    bool rolling_rule_passed;
    int32_t vertical_impulse_milli_mps;
    int32_t gyro_mean_milli_rads;
    int32_t axis_consistency_milli;
};

void motion_demo_v0_init(struct motion_demo_v0 *context);
bool motion_demo_v0_push(struct motion_demo_v0 *context,
                         const struct motion_demo_v0_sample *sample);
void motion_demo_v0_get_snapshot(const struct motion_demo_v0 *context,
                                 struct motion_demo_v0_snapshot *snapshot);
const char *motion_demo_v0_state_name(enum motion_demo_v0_state state);
const char *motion_demo_v0_event_name(enum motion_demo_v0_event event);

#ifdef __cplusplus
}
#endif

#endif /* PUTTTRACK_MOTION_DEMO_V0_H_ */
```

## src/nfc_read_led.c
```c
#include <errno.h>
#include <zephyr/drivers/gpio.h>
#include <zephyr/kernel.h>
#include <zephyr/sys/atomic.h>
#include "nfc_read_led.h"

static const struct gpio_dt_spec led = GPIO_DT_SPEC_GET(DT_ALIAS(led0), gpios);
static struct k_work pulse_work;
static struct k_work_delayable off_work;
static atomic_t ready;
static atomic_t pending;
static atomic_t error;
static atomic_t pulses;
static int64_t last_pulse = -1000;

static void turn_off(struct k_work *work)
{
	ARG_UNUSED(work);
	atomic_set(&error, gpio_pin_set_dt(&led, 0));
	atomic_clear(&pending);
}

static void pulse(struct k_work *work)
{
	ARG_UNUSED(work);
	const int64_t now = k_uptime_get();
	if (!atomic_get(&ready) || now - last_pulse < 1000) {
		atomic_clear(&pending);
		return;
	}
	int rc = gpio_pin_set_dt(&led, 1);
	atomic_set(&error, rc);
	if (rc) {
		atomic_clear(&pending);
		return;
	}
	last_pulse = now;
	atomic_inc(&pulses);
	(void)k_work_reschedule(&off_work, K_MSEC(150));
}

void nfc_read_led_init(void)
{
	k_work_init(&pulse_work, pulse);
	k_work_init_delayable(&off_work, turn_off);
	int rc = gpio_is_ready_dt(&led) ? gpio_pin_configure_dt(&led, GPIO_OUTPUT_INACTIVE) : -ENODEV;
	atomic_set(&error, rc);
	atomic_set(&ready, rc == 0);
}

void nfc_read_led_notify(void)
{
	/* NFCT callback only queues work: no delays or GPIO transactions in IRQ. */
	if (atomic_get(&ready) && atomic_cas(&pending, 0, 1)) {
		(void)k_work_submit(&pulse_work);
	}
}

void nfc_read_led_stop(void)
{
	/* Called from the same system workqueue before System OFF. */
	atomic_clear(&ready);
	(void)k_work_cancel(&pulse_work);
	(void)k_work_cancel_delayable(&off_work);
	if (gpio_is_ready_dt(&led)) {
		atomic_set(&error, gpio_pin_set_dt(&led, 0));
	}
	atomic_clear(&pending);
}

int nfc_read_led_error(void) { return atomic_get(&error); }
unsigned int nfc_read_led_pulses(void) { return (unsigned int)atomic_get(&pulses); }
```

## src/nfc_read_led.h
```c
#pragma once

#if defined(CONFIG_PUTTTRACK_NFC_READ_LED)
void nfc_read_led_init(void);
void nfc_read_led_notify(void);
void nfc_read_led_stop(void);
int nfc_read_led_error(void);
unsigned int nfc_read_led_pulses(void);
#else
static inline void nfc_read_led_init(void) {}
static inline void nfc_read_led_notify(void) {}
static inline void nfc_read_led_stop(void) {}
static inline int nfc_read_led_error(void) { return 0; }
static inline unsigned int nfc_read_led_pulses(void) { return 0; }
#endif
```

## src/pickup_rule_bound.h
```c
#ifndef PUTTTRACK_PICKUP_RULE_BOUND_H
#define PUTTTRACK_PICKUP_RULE_BOUND_H

#include <stdbool.h>
#include <stdint.h>

/*
 * Research primitive only. This does not alter frozen Pickup V0 and has no
 * Gameplay/scoring authority.
 *
 * The current stationary-start Pickup V0 requires mean_gyro_norm < 10 rad/s.
 * If k of N samples have at least one gyro axis at the BMI270 clipping boundary
 * (34.208453 rad/s), then mean_gyro_norm >= k/N * 34.208453 rad/s.
 *
 * REJECTED therefore means only that the existing mean-gyro predicate cannot
 * hold for this complete, valid window. It does NOT mean physical pickup is
 * impossible and does NOT classify the motion as rolling.
 *
 * Caller responsibilities before invoking:
 * - validated identity / device / boot context;
 * - valid sequence and monotonic time continuity;
 * - valid sensor health;
 * - complete feature window and expected sampling definition;
 * - stationary-start context;
 * - clipping count uses the exact configured per-sample definition.
 */

typedef enum {
    PT_BOUND_UNAVAILABLE = 0,
    PT_BOUND_NO_CONCLUSION = 1,
    PT_PICKUP_RULE_REJECTED = 2
} pt_pickup_bound_result;

static inline pt_pickup_bound_result pt_pickup_rule_bound(
    bool window_valid,
    uint32_t sample_count,
    uint32_t clipped_count)
{
    if (!window_valid || sample_count == 0U || clipped_count > sample_count) {
        return PT_BOUND_UNAVAILABLE;
    }

    /*
     * Fixed-point form of:
     *   clipped_count / sample_count * 34.208453 >= 10.0
     *
     * Strict Pickup V0 predicate is '< 10', so equality rejects it.
     * uint64_t avoids intermediate overflow.
     */
    if ((uint64_t)clipped_count * UINT64_C(34208453) >=
        (uint64_t)sample_count * UINT64_C(10000000)) {
        return PT_PICKUP_RULE_REJECTED;
    }

    return PT_BOUND_NO_CONCLUSION;
}

#endif /* PUTTTRACK_PICKUP_RULE_BOUND_H */
```

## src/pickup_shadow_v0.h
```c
/*
 * Frozen Pickup V0 evaluation kernel shared by nRF54L15 firmware and native
 * parity tests. Results are research-only shadow evidence, never Gameplay
 * authority.
 */

#ifndef PUTTTRACK_PICKUP_SHADOW_V0_H_
#define PUTTTRACK_PICKUP_SHADOW_V0_H_

#include <stdbool.h>
#include <stddef.h>
#include <stdint.h>

#ifdef __cplusplus
extern "C" {
#endif

enum pt_pickup_shadow_decision {
	PT_PICKUP_SHADOW_UNARMED = 0,
	PT_PICKUP_SHADOW_PENDING = 1,
	PT_PICKUP_SHADOW_SUSPECTED = 2,
	PT_PICKUP_SHADOW_NOT_PICKUP = 3,
	PT_PICKUP_SHADOW_UNKNOWN = 4,
};

enum pt_pickup_shadow_reason {
	PT_PICKUP_REASON_INSUFFICIENT_SAMPLES = (1U << 0),
	PT_PICKUP_REASON_SEQUENCE = (1U << 1),
	PT_PICKUP_REASON_TIME = (1U << 2),
	PT_PICKUP_REASON_SENSOR_INVALID = (1U << 3),
	PT_PICKUP_REASON_SOURCE_RATE = (1U << 4),
	PT_PICKUP_REASON_BASELINE_SAMPLES = (1U << 5),
	PT_PICKUP_REASON_BASELINE_NOT_STATIONARY = (1U << 6),
	PT_PICKUP_REASON_FEATURE_WINDOW = (1U << 7),
	PT_PICKUP_REASON_GYRO_CLIPPING = (1U << 8),
	PT_PICKUP_REASON_POSITIVE_IMPULSE = (1U << 9),
	PT_PICKUP_REASON_MEAN_GYRO = (1U << 10),
	PT_PICKUP_REASON_AXIS_CONSISTENCY = (1U << 11),
	PT_PICKUP_REASON_NO_MOTION_ONSET = (1U << 12),
};

#define PT_PICKUP_RULE_POSITIVE_IMPULSE (1U << 0)
#define PT_PICKUP_RULE_MEAN_GYRO (1U << 1)
#define PT_PICKUP_RULE_AXIS_CONSISTENCY (1U << 2)

#define PT_PICKUP_SHADOW_DETECTOR_ID "pickup_detector_v0_stationary_start"
#define PT_PICKUP_SHADOW_DETECTOR_SHA256 \
	"62c82c1a313f70912a5bb6c2f53c635fe179c537cdb3738dbc5d2a347050c8ad"

struct pt_pickup_sample {
	uint32_t sequence;
	uint64_t source_monotonic_us;
	int32_t accel_micro_ms2[3];
	int32_t gyro_micro_rads[3];
	uint32_t sensor_error_bits;
	uint8_t adxl367_valid;
	uint8_t bmi270_valid;
	uint8_t reserved[2];
};

struct pt_pickup_shadow_result {
	uint32_t decision;
	uint32_t reason_mask;
	uint32_t rule_pass_mask;
	uint32_t baseline_sample_count;
	uint32_t feature_sample_count_gyro;
	uint32_t feature_sample_count_impulse;
	uint32_t gyro_clip_samples;
	uint64_t onset_source_monotonic_us;
	double source_rate_hz;
	double baseline_duration_s;
	double baseline_accel_norm_stdev_mps2;
	double baseline_gyro_norm_rms_rads;
	double onset_offset_from_go_s;
	double positive_vertical_impulse_mps;
	double mean_gyro_norm_1s_rads;
	double gyro_axis_consistency_1s;
};

/* Minimum time after GO before a no-onset result is final in live mode. */
#define PT_PICKUP_SHADOW_LIVE_OBSERVATION_US 3000000ULL

void pt_pickup_shadow_evaluate(const struct pt_pickup_sample *samples,
			       size_t sample_count, uint64_t go_us,
			       bool live_mode,
			       struct pt_pickup_shadow_result *result);

const char *pt_pickup_shadow_decision_name(uint32_t decision);

#ifdef __cplusplus
}
#endif

#endif /* PUTTTRACK_PICKUP_SHADOW_V0_H_ */
```

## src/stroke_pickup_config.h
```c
/* Generated; use tools/generate_stroke_pickup_config.py. */
#ifndef PT_STROKE_PICKUP_CONFIG_H
#define PT_STROKE_PICKUP_CONFIG_H
#define SPV1_ID "stroke_pickup_shadow_v1"
#define SPV1_CONFIG_SHA256 "ad9ea020ebbf6ee4de00afbcea2d18e4633e84de36758f2aebb5a2ddf94fb361"
#define SPV1_ACCEL_NEAR_RAIL_MPS2 153.768272f
#define SPV1_BASELINE_ACCEL_NORM_MAX_MPS2 12.0f
#define SPV1_BASELINE_ACCEL_NORM_MIN_MPS2 8.0f
#define SPV1_CONTACT_DELTA_MPS2 8.0f
#define SPV1_CONTACT_MERGE_US 250000U
#define SPV1_DECISION_WINDOW_US 1000000U
#define SPV1_DEVELOPMENT_REVISION 3U
#define SPV1_EARLY_IMPACT_WINDOW_US 160000U
#define SPV1_EVENT_CAPACITY 16U
#define SPV1_GYRO_NEAR_RAIL_RADS 34.208453f
#define SPV1_IMPULSE_WINDOW_US 600000U
#define SPV1_MAXIMUM_DT_US 30000U
#define SPV1_MINIMUM_DT_US 15000U
#define SPV1_ONSET_ACCEL_DEVIATION_MPS2 0.5f
#define SPV1_ONSET_GYRO_RADS 0.25f
#define SPV1_PICKUP_MEAN_GYRO_MAX_RADS 10.0f
#define SPV1_PICKUP_POSITIVE_IMPULSE_MIN_MPS 0.5f
#define SPV1_PICKUP_SCORE_MIN 2.5f
#define SPV1_QUIET_ACCEL_DEVIATION_MPS2 0.2f
#define SPV1_QUIET_DWELL_US 900000U
#define SPV1_QUIET_GYRO_RADS 0.08f
#define SPV1_RATE_HZ 50U
#define SPV1_SCHEMA_VERSION 1U
#define SPV1_STROKE_DECISION_WINDOW_US 200000U
#define SPV1_STROKE_DIRECTION_MIN 0.8f
#define SPV1_STROKE_MEAN_GYRO_MIN_RADS 8.0f
#endif
```

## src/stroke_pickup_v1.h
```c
/* SPDX-License-Identifier: Apache-2.0 */
#ifndef PT_STROKE_PICKUP_V1_H
#define PT_STROKE_PICKUP_V1_H
#include <stdbool.h>
#include <stddef.h>
#include <stdint.h>
#include "stroke_pickup_config.h"

/* Candidate counters are telemetry, NEVER authoritative strokes or penalties. */
enum spv1_state { SP_BOOTSTRAP, SP_QUIET, SP_MOVING, SP_ROTATION, SP_DEGRADED };
enum spv1_event_type {
    SP_STROKE_LIKE = 1, SP_PICKUP_SUSPECTED, SP_CONTACT_MOVING,
    SP_ONSET_UNRESOLVED, SP_QUALITY_BREAK, SP_STROKE_PENDING
};
enum spv1_quality {
    SP_SENSOR = 1U, SP_SEQUENCE = 2U, SP_TIME = 4U,
    SP_ACCEL_RAIL = 8U, SP_GYRO_RAIL = 16U, SP_NO_BASELINE = 32U,
    SP_WINDOW = 64U, SP_HELD_CONTEXT = 128U, SP_COUNTER_OVERFLOW = 256U
};
enum spv1_reason {
    SP_HAS_EARLY_TRANSIENT = 1U, SP_HAS_ROTATION = 2U,
    SP_HAS_LIFT_SCORE = 4U, SP_NEEDS_CONTACT_SOURCE = 8U,
    SP_FROM_MOVING = 16U, SP_WEAK_OR_UNSUPPORTED = 32U,
    SP_HELD_UNRESOLVED = 64U, SP_INTERRUPTED = 128U
};
struct spv1_sample {
    uint32_t sequence;
    uint64_t time_us;
    int32_t accel_micro[3], gyro_micro[3];
    bool valid;
    uint32_t sensor_errors;
};
/* Fixed wire layout is serialized explicitly, not by dumping this structure. */
struct spv1_event {
    uint32_t id, type, reason, quality, onset_seq, end_seq;
    uint64_t onset_us, decision_us;
    int32_t impulse_milli, gyro_mean_milli;
    uint32_t direction_milli, axial_milli, impact_milli, clip_permille;
};
struct spv1_window {
    bool active, up_valid, stroke_checked, stroke_pending;
    uint64_t start_us;
    uint32_t start_seq, samples, active_samples, clip_samples, quality;
    float up[3], gravity, impulse, gyro_sum, gyro_vector[3], moment[6];
    float impact_max;
};
struct spv1_context {
    struct spv1_event events[SPV1_EVENT_CAPACITY];
    struct spv1_window window;
    enum spv1_state state;
    bool have_previous, armed, held_hint, count_incomplete;
    uint32_t generation, latest_id, event_count, overwritten;
    uint32_t stroke_candidates, pickup_candidates, ambiguous_contacts, unknown_onsets;
    uint32_t quality_breaks, current_quality, source_sequence;
    uint64_t source_us, quiet_start_us, last_contact_us;
    uint32_t quiet_samples;
    float quiet_accel_sum[3], quiet_norm_mean, gravity, previous_accel[3], previous_gyro[3];
};
void spv1_init(struct spv1_context *c);
void spv1_invalidate(struct spv1_context *c);
/* Explicit operator bench boundary only, never inferred from IMU quietness. */
void spv1_new_trial(struct spv1_context *c);
void spv1_push(struct spv1_context *c, const struct spv1_sample *s);
/* Copy chronological events. Caller must hold its application mutex. */
size_t spv1_events(const struct spv1_context *c, struct spv1_event *out, size_t capacity);
const char *spv1_event_name(uint32_t type);
#endif
```

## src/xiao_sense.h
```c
/* SPDX-License-Identifier: Apache-2.0 */
#pragma once
#include <zephyr/drivers/sensor.h>
int pt_xiao_init(void);
int pt_xiao_active(void);
int pt_xiao_idle(void);
int pt_xiao_sample(struct sensor_value accel[3], struct sensor_value gyro[3]);
int pt_xiao_wake_enable(void (*notify)(void));
int pt_xiao_wake_disable(void);
bool pt_xiao_ready(void);
```
